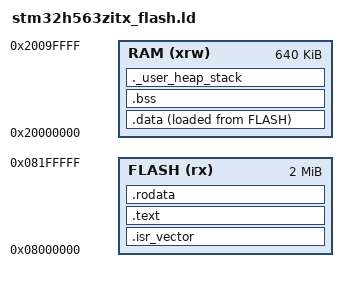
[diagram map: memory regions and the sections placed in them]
/* Entry Point */
ENTRY(Reset_Handler)

/* Memories definition */
MEMORY
{
  RAM   (xrw) : ORIGIN = 0x20000000, LENGTH = 640K
  FLASH (rx)  : ORIGIN = 0x08000000, LENGTH = 2048K
}

/* Highest address of the user mode stack */
__stack_top = ORIGIN(RAM) + LENGTH(RAM); /* end of "RAM" Ram type memory */

_Min_Heap_Size = 0x200; /* required amount of heap */
_Min_Stack_Size = 0x400; /* required amount of stack */

/* Sections */
SECTIONS
{
  /* The startup code into "FLASH" Rom type memory */
  .isr_vector :
  {
    . = ALIGN(4);
    LONG(__stack_top);
    KEEP(*(.isr_vector)) /* Startup code */
    . = ALIGN(4);
  } >FLASH

  /* The program code and other data into "FLASH" Rom type memory */
  .text :
  {
    . = ALIGN(4);
    *(.text)           /* .text sections (code) */
    *(.text*)          /* .text* sections (code) */
    . = ALIGN(4);
    __text_end = .;
  } >FLASH

  /* Constant data into "FLASH" Rom type memory */
  .rodata :
  {
    . = ALIGN(4);
    *(.rodata)         /* .rodata sections (constants, strings, etc.) */
    *(.rodata*)        /* .rodata* sections (constants, strings, etc.) */
    . = ALIGN(4);
  } >FLASH


  /* Initialized data sections into "RAM" Ram type memory */
  .data : 
  {
    . = ALIGN(4);
    *(.data)           /* .data sections */
    *(.data*)          /* .data* sections */
    *(.RamFunc)        /* .RamFunc sections */
    *(.RamFunc*)       /* .RamFunc* sections */
    . = ALIGN(4);
  } >RAM AT> FLASH
  __data_start_ram = ADDR(.data);
  __data_start_flash = LOADADDR(.data);
  __data_size = SIZEOF(.data);
  

  /* Uninitialized data section into "RAM" Ram type memory */
  . = ALIGN(4);
  .bss :
  {
    /* This is used by the startup in order to initialize the .bss section */
    __bss_start = .;
    *(.bss)
    *(.bss*)
    *(COMMON)

    . = ALIGN(4);
    __bss_end = .;
  } >RAM

  __bss_size = __bss_end - __bss_start;

  /* User_heap_stack section, used to check that there is enough "RAM" Ram  type memory left */
  ._user_heap_stack :
  {
    . = ALIGN(8);
    PROVIDE ( end = . );
    PROVIDE ( _end = . );
    . = . + _Min_Heap_Size;
    . = . + _Min_Stack_Size;
    . = ALIGN(8);
  } >RAM

  /* Remove information from the compiler libraries */
  /DISCARD/ :
  {
    libc.a ( * )
    libm.a ( * )
    libgcc.a ( * )
  }

  .ARM.attributes 0 : { *(.ARM.attributes) }
}
